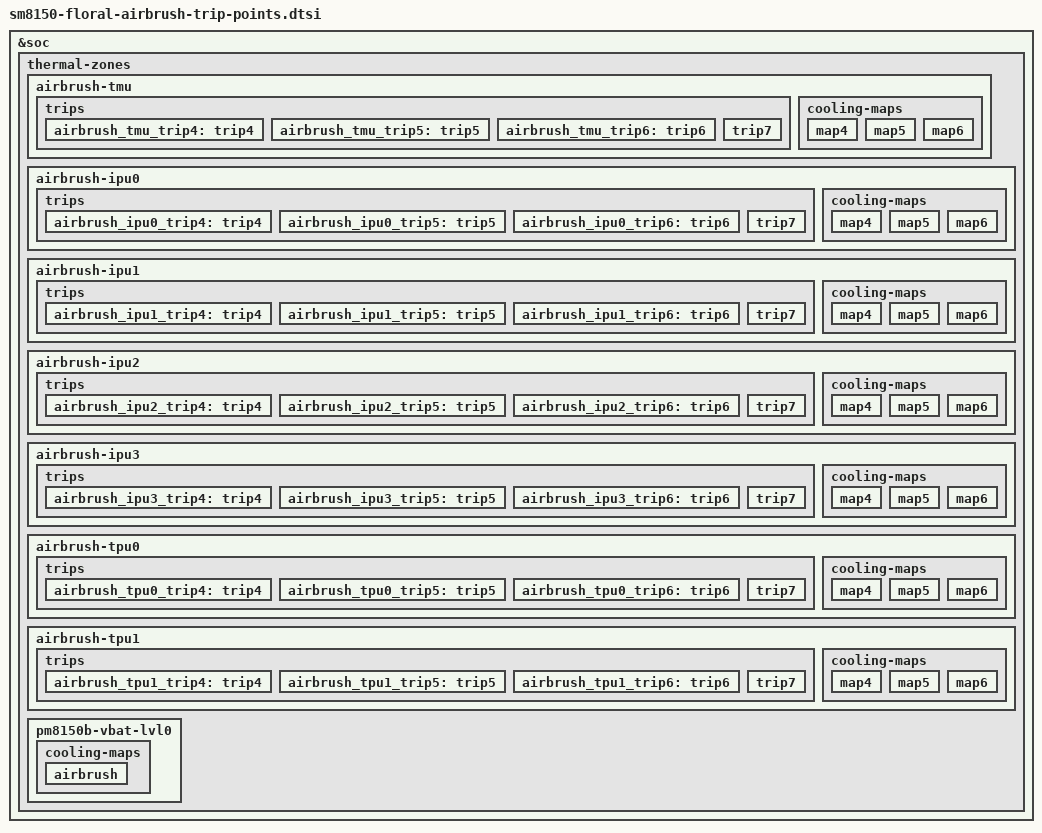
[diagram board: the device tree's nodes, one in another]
/*
 * Copyright (c) 2016 Samsung Electronics Co., Ltd.
 *		http://www.samsung.com
 *
 * This program is free software; you can redistribute it and/or modify
 * it under the terms of the GNU General Public License version 2 as
 * published by the Free Software Foundation.
 *
 */

#include <dt-bindings/thermal/airbrush_tmu.h>

/*
 * The 7-th trip point (trip7) of each airbruhs-* thermal zone would trigger
 * the TH_TRIP and Airbrush PMIC interrupt for emergency shutdown.  Set to 130C
 * to protect Airbrush die from damaged.  Airbrush DDR needs to be under 85C
 * for working properly, so the limit should be set to trigger thermal
 * throttling instead.
 */

&soc {
	thermal-zones {
		airbrush-tmu {
			/*
			 * TMU is able to emit interrupt to update the thermal
			 * zone while temperature going across the trip points.
			 * Also, each write to emul_temp will always update the
			 * thermal zone. So we set the polling-delay-* to 0.
			 */
			polling-delay-passive = <0>;
			polling-delay = <0>;
			thermal-sensors =
				<&airbrush_tmu AB_TMU_TEMP_PROBE_MAIN>;
			wake-capable-sensor;
			trips {
			/include/ "sm8150-floral-airbrush-dummy-trips.dtsi"
				airbrush_tmu_trip4: trip4 {
					temperature = <65000>;
					hysteresis = <1000>;
					type = "passive";
				};
				airbrush_tmu_trip5: trip5 {
					temperature = <75000>;
					hysteresis = <1000>;
					type = "passive";
				};
				airbrush_tmu_trip6: trip6 {
					temperature = <85000>;
					hysteresis = <1000>;
					type = "passive";
				};
				trip7 {
					temperature = <105000>;
					hysteresis = <0>;
					type = "hot";
				};
			};
			cooling-maps {
				map4 {
					trip = <&airbrush_tmu_trip4>;
					cooling-device =
						<&abc_cooling_internal 1 1>;
				};
				map5 {
					trip = <&airbrush_tmu_trip5>;
					cooling-device =
						<&abc_cooling_internal 2 2>;
				};
				map6 {
					trip = <&airbrush_tmu_trip6>;
					cooling-device =
						<&abc_cooling_internal 3 3>;
				};
			};
		};

		airbrush-ipu0 {
			polling-delay-passive = <0>;
			polling-delay = <0>;
			thermal-sensors =
				<&airbrush_tmu AB_TMU_TEMP_PROBE_IPU0>;
			wake-capable-sensor;
			trips {
			/include/ "sm8150-floral-airbrush-dummy-trips.dtsi"
				airbrush_ipu0_trip4: trip4 {
					temperature = <65000>;
					hysteresis = <1000>;
					type = "passive";
				};
				airbrush_ipu0_trip5: trip5 {
					temperature = <75000>;
					hysteresis = <1000>;
					type = "passive";
				};
				airbrush_ipu0_trip6: trip6 {
					temperature = <85000>;
					hysteresis = <1000>;
					type = "passive";
				};
				trip7 {
					temperature = <105000>;
					hysteresis = <0>;
					type = "hot";
				};
			};
			cooling-maps {
				map4 {
					trip = <&airbrush_ipu0_trip4>;
					cooling-device =
						<&abc_cooling_internal 1 1>;
				};
				map5 {
					trip = <&airbrush_ipu0_trip5>;
					cooling-device =
						<&abc_cooling_internal 2 2>;
				};
				map6 {
					trip = <&airbrush_ipu0_trip6>;
					cooling-device =
						<&abc_cooling_internal 3 3>;
				};
			};
		};

		airbrush-ipu1 {
			polling-delay-passive = <0>;
			polling-delay = <0>;
			thermal-sensors =
				<&airbrush_tmu AB_TMU_TEMP_PROBE_IPU1>;
			wake-capable-sensor;
			trips {
			/include/ "sm8150-floral-airbrush-dummy-trips.dtsi"
				airbrush_ipu1_trip4: trip4 {
					temperature = <65000>;
					hysteresis = <1000>;
					type = "passive";
				};
				airbrush_ipu1_trip5: trip5 {
					temperature = <75000>;
					hysteresis = <1000>;
					type = "passive";
				};
				airbrush_ipu1_trip6: trip6 {
					temperature = <85000>;
					hysteresis = <1000>;
					type = "passive";
				};
				trip7 {
					temperature = <105000>;
					hysteresis = <0>;
					type = "hot";
				};
			};
			cooling-maps {
				map4 {
					trip = <&airbrush_ipu1_trip4>;
					cooling-device =
						<&abc_cooling_internal 1 1>;
				};
				map5 {
					trip = <&airbrush_ipu1_trip5>;
					cooling-device =
						<&abc_cooling_internal 2 2>;
				};
				map6 {
					trip = <&airbrush_ipu1_trip6>;
					cooling-device =
						<&abc_cooling_internal 3 3>;
				};
			};
		};

		airbrush-ipu2 {
			polling-delay-passive = <0>;
			polling-delay = <0>;
			thermal-sensors =
				<&airbrush_tmu AB_TMU_TEMP_PROBE_IPU2>;
			wake-capable-sensor;
			trips {
			/include/ "sm8150-floral-airbrush-dummy-trips.dtsi"
				airbrush_ipu2_trip4: trip4 {
					temperature = <65000>;
					hysteresis = <1000>;
					type = "passive";
				};
				airbrush_ipu2_trip5: trip5 {
					temperature = <75000>;
					hysteresis = <1000>;
					type = "passive";
				};
				airbrush_ipu2_trip6: trip6 {
					temperature = <85000>;
					hysteresis = <1000>;
					type = "passive";
				};
				trip7 {
					temperature = <105000>;
					hysteresis = <0>;
					type = "hot";
				};
			};
			cooling-maps {
				map4 {
					trip = <&airbrush_ipu2_trip4>;
					cooling-device =
						<&abc_cooling_internal 1 1>;
				};
				map5 {
					trip = <&airbrush_ipu2_trip5>;
					cooling-device =
						<&abc_cooling_internal 2 2>;
				};
				map6 {
					trip = <&airbrush_ipu2_trip6>;
					cooling-device =
						<&abc_cooling_internal 3 3>;
				};
			};
		};

		airbrush-ipu3 {
			polling-delay-passive = <0>;
			polling-delay = <0>;
			thermal-sensors =
				<&airbrush_tmu AB_TMU_TEMP_PROBE_IPU_TPU>;
			wake-capable-sensor;
			trips {
			/include/ "sm8150-floral-airbrush-dummy-trips.dtsi"
				airbrush_ipu3_trip4: trip4 {
					temperature = <65000>;
					hysteresis = <1000>;
					type = "passive";
				};
				airbrush_ipu3_trip5: trip5 {
					temperature = <75000>;
					hysteresis = <1000>;
					type = "passive";
				};
				airbrush_ipu3_trip6: trip6 {
					temperature = <85000>;
					hysteresis = <1000>;
					type = "passive";
				};
				trip7 {
					temperature = <105000>;
					hysteresis = <0>;
					type = "hot";
				};
			};
			cooling-maps {
				map4 {
					trip = <&airbrush_ipu3_trip4>;
					cooling-device =
						<&abc_cooling_internal 1 1>;
				};
				map5 {
					trip = <&airbrush_ipu3_trip5>;
					cooling-device =
						<&abc_cooling_internal 2 2>;
				};
				map6 {
					trip = <&airbrush_ipu3_trip6>;
					cooling-device =
						<&abc_cooling_internal 3 3>;
				};
			};
		};

		airbrush-tpu0 {
			polling-delay-passive = <0>;
			polling-delay = <0>;
			thermal-sensors =
				<&airbrush_tmu AB_TMU_TEMP_PROBE_TPU0>;
			wake-capable-sensor;
			trips {
			/include/ "sm8150-floral-airbrush-dummy-trips.dtsi"
				airbrush_tpu0_trip4: trip4 {
					temperature = <65000>;
					hysteresis = <1000>;
					type = "passive";
				};
				airbrush_tpu0_trip5: trip5 {
					temperature = <75000>;
					hysteresis = <1000>;
					type = "passive";
				};
				airbrush_tpu0_trip6: trip6 {
					temperature = <85000>;
					hysteresis = <1000>;
					type = "passive";
				};
				trip7 {
					temperature = <105000>;
					hysteresis = <0>;
					type = "hot";
				};
			};
			cooling-maps {
				map4 {
					trip = <&airbrush_tpu0_trip4>;
					cooling-device =
						<&abc_cooling_internal 1 1>;
				};
				map5 {
					trip = <&airbrush_tpu0_trip5>;
					cooling-device =
						<&abc_cooling_internal 2 2>;
				};
				map6 {
					trip = <&airbrush_tpu0_trip6>;
					cooling-device =
						<&abc_cooling_internal 3 3>;
				};
			};
		};

		airbrush-tpu1 {
			polling-delay-passive = <0>;
			polling-delay = <0>;
			thermal-sensors =
				<&airbrush_tmu AB_TMU_TEMP_PROBE_TPU1>;
			wake-capable-sensor;
			trips {
			/include/ "sm8150-floral-airbrush-dummy-trips.dtsi"
				airbrush_tpu1_trip4: trip4 {
					temperature = <65000>;
					hysteresis = <1000>;
					type = "passive";
				};
				airbrush_tpu1_trip5: trip5 {
					temperature = <75000>;
					hysteresis = <1000>;
					type = "passive";
				};
				airbrush_tpu1_trip6: trip6 {
					temperature = <85000>;
					hysteresis = <1000>;
					type = "passive";
				};
				trip7 {
					temperature = <105000>;
					hysteresis = <0>;
					type = "hot";
				};
			};
			cooling-maps {
				map4 {
					trip = <&airbrush_tpu1_trip4>;
					cooling-device =
						<&abc_cooling_internal 1 1>;
				};
				map5 {
					trip = <&airbrush_tpu1_trip5>;
					cooling-device =
						<&abc_cooling_internal 2 2>;
				};
				map6 {
					trip = <&airbrush_tpu1_trip6>;
					cooling-device =
						<&abc_cooling_internal 3 3>;
				};
			};
		};

		pm8150b-vbat-lvl0 {
			cooling-maps {
				airbrush {
					trip = <&vbat_lvl0>;
					cooling-device = <&abc_cooling_bcl 3 3>;
				};
			};
		};
	};
};

